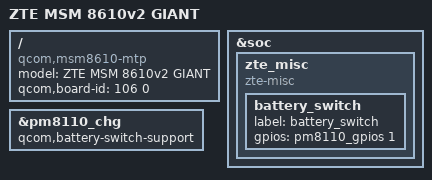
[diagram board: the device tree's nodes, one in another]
/* Copyright (c) 2013, The Linux Foundation. All rights reserved.
 *
 * This program is free software; you can redistribute it and/or modify
 * it under the terms of the GNU General Public License version 2 and
 * only version 2 as published by the Free Software Foundation.
 *
 * This program is distributed in the hope that it will be useful,
 * but WITHOUT ANY WARRANTY; without even the implied warranty of
 * MERCHANTABILITY or FITNESS FOR A PARTICULAR PURPOSE.  See the
 * GNU General Public License for more details.
 */

/dts-v1/;

/include/ "msm8610-v2.dtsi"
/include/ "msm8610-mtp.dtsi"
/include/ "msm8610-camera-sensor-cdp-mtp.dtsi"
/include/ "zte-msm8610-giant.dtsi"

/ {
	model = "ZTE MSM 8610v2 GIANT";
	compatible = "qcom,msm8610-mtp", "qcom,msm8610", "qcom,mtp";
	qcom,board-id = <106 0>;
};

&soc {
	zte_misc {
		compatible = "zte-misc";

		battery_switch {
		label = "battery_switch";
		gpios = <&pm8110_gpios 1 0x0>;
		};
	};
};

&pm8110_chg {
	qcom,battery-switch-support;
};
